# VIRTIO_MMIO register map
File version: 2
Registers are write-only, no defined reset value unless marked. A register's access mark holds for its fields unless they carry their own. Offsets are from the block's base; [hi:lo] are bit positions; lines under a group give offsets from that group; {n}, {i} and the like mark numbered series.

## VIRTIO_BLK — The block device (section 5.2): the transport and struct virtio_blk_config (5.2.4)
Base 0x00000000
0x00 TRANSPORT group — The virtio-mmio transport
  0x00 MAGIC ro — Magic value, 0x74726976 ("virt" in little-endian order)
    [31:0] VALUE
  0x04 VERSION ro — Device version number, 2 for the non-legacy interface
    [31:0] VALUE
  0x08 DEVICE_ID ro — Virtio subsystem device ID, 0 for a transport with no device
    [31:0] VALUE
  0x0C VENDOR_ID ro — Virtio subsystem vendor ID
    [31:0] VALUE
  0x10 DEVICE_FEATURES ro — The 32 feature bits of the word DEVICE_FEATURES_SEL selects
    [31:0] VALUE
  0x14 DEVICE_FEATURES_SEL — Selects the word of the device's feature bits DEVICE_FEATURES shows
    [31:0] VALUE
  0x20 DRIVER_FEATURES — The 32 feature bits the driver accepts, of the word DRIVER_FEATURES_SEL selects
    [31:0] VALUE
  0x24 DRIVER_FEATURES_SEL — Selects the word of the driver's feature bits DRIVER_FEATURES writes
    [31:0] VALUE
  0x30 QUEUE_SEL — Selects the queue the QUEUE_ registers below address
    [31:0] VALUE
  0x34 QUEUE_NUM_MAX ro — The largest size of the selected queue, 0 when the queue is not available
    [31:0] VALUE
  0x38 QUEUE_NUM — The size of the selected queue, a power of two up to QUEUE_NUM_MAX
    [31:0] VALUE
  0x44 QUEUE_READY rw — Whether the device may use the selected queue
    [0] READY
  0x50 QUEUE_NOTIFY — The doorbell: the index of a queue with new available buffers
    [31:0] VALUE
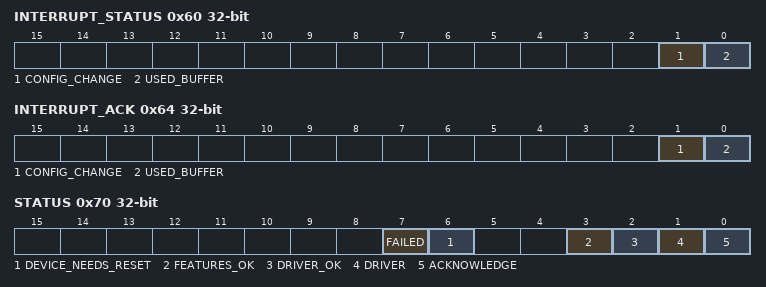
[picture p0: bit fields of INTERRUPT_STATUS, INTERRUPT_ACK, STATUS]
  0x60 INTERRUPT_STATUS ro — Why the device raised its interrupt
    [1] CONFIG_CHANGE — the configuration space changed
    [0] USED_BUFFER — a queue's used ring changed
  0x64 INTERRUPT_ACK — Acknowledges the interrupt causes written as ones
    [1] CONFIG_CHANGE write-1-clears, [0] USED_BUFFER write-1-clears
  0x70 STATUS rw — Device status; writing zero resets the device
    [7] FAILED, [6] DEVICE_NEEDS_RESET ro, [3] FEATURES_OK, [2] DRIVER_OK, [1] DRIVER, [0] ACKNOWLEDGE
  0x80 QUEUE_DESC_LOW — Low half of the selected queue's descriptor table address
    [31:0] VALUE
  0x84 QUEUE_DESC_HIGH — High half of the selected queue's descriptor table address
    [31:0] VALUE
  0x90 QUEUE_DRIVER_LOW — Low half of the selected queue's available ring address
    [31:0] VALUE
  0x94 QUEUE_DRIVER_HIGH — High half of the selected queue's available ring address
    [31:0] VALUE
  0xA0 QUEUE_DEVICE_LOW — Low half of the selected queue's used ring address
    [31:0] VALUE
  0xA4 QUEUE_DEVICE_HIGH — High half of the selected queue's used ring address
    [31:0] VALUE
  0xFC CONFIG_GENERATION ro — Changes whenever the configuration space changes
    [31:0] VALUE
0x100 CAPACITY_LOW ro — Low half of the capacity in 512-byte sectors, a 64-bit field read as two 32-bit words
  [31:0] VALUE
0x104 CAPACITY_HIGH ro — High half of the capacity in 512-byte sectors
  [31:0] VALUE

## VIRTIO_NET — The network device (section 5.1): the transport and the fields of struct virtio_net_config (5.1.4) the driver reads
Base 0x00000000
Registers as VIRTIO_BLK, without CAPACITY_LOW, CAPACITY_HIGH; these are added or differ:
{0x100+i} MAC[{i}] (i=0..5) 8-bit ro — The device's MAC address, one byte each, valid when VIRTIO_NET_F_MAC is offered
  [7:0] VALUE
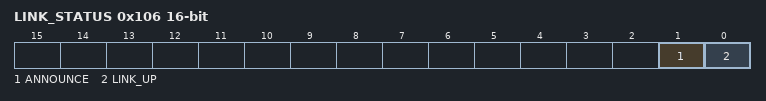
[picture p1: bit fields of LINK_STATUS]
0x106 LINK_STATUS 16-bit ro — The link status, the specification's status field, valid when VIRTIO_NET_F_STATUS is offered
  [1] ANNOUNCE, [0] LINK_UP
0x10A MTU 16-bit ro — The largest MTU the driver should use, valid when VIRTIO_NET_F_MTU is offered
  [15:0] VALUE

## VIRTIO_INPUT — The input device (section 5.8): the transport and the fields of struct virtio_input_config (5.8.4) the driver uses
Base 0x00000000
Registers as VIRTIO_BLK, without CAPACITY_LOW, CAPACITY_HIGH; these are added or differ:
0x100 SELECT 8-bit rw — What the configuration answers, with SUBSEL; the driver sets both (5.8.5.1)
  [7:0] VALUE
    0=UNSET; 1=ID_NAME; 2=ID_SERIAL; 3=ID_DEVIDS; 16=PROP_BITS; 17=EV_BITS; 18=ABS_INFO
0x101 SUBSEL 8-bit rw — The item SELECT asks about, such as an axis's evdev code
  [7:0] VALUE
0x102 SIZE 8-bit ro — The bytes of the answer, 0 when the device has none for SELECT and SUBSEL
  [7:0] VALUE
0x108 ABS_MIN ro — An ABS_INFO answer's min, the first word of struct virtio_input_absinfo, signed
  [31:0] VALUE
0x10C ABS_MAX ro — An ABS_INFO answer's max, signed
  [31:0] VALUE

## Notices in the file
Copyright (c) 2026, Stanislav Sedov <stas@deglitch.com>
SPDX-License-Identifier: BSD-2-Clause
